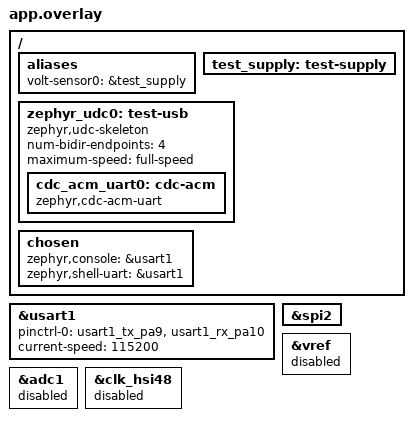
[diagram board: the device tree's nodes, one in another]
/* SPDX-License-Identifier: MIT */
#include "../../app/app.overlay"

/* Use the Zephyr USB stack and CDC ACM class with a software controller. */
/delete-node/ &zephyr_udc0;

/ {
	aliases {
		volt-sensor0 = &test_supply;
	};
	test_supply: test-supply {
	};
	zephyr_udc0: test-usb {
		compatible = "zephyr,udc-skeleton";
		num-bidir-endpoints = <4>;
		maximum-speed = "full-speed";
		cdc_acm_uart0: cdc-acm {
			compatible = "zephyr,cdc-acm-uart";
		};
	};
	chosen {
		zephyr,console = &usart1;
		zephyr,shell-uart = &usart1;
	};
};

&usart1 {
	pinctrl-0 = <&usart1_tx_pa9 &usart1_rx_pa10>;
	pinctrl-names = "default";
	current-speed = <115200>;
	status = "okay";
};

/* Exercise the pixel driver without the board's SPI DMA requests. */
&spi2 {
	/delete-property/ dmas;
	/delete-property/ dma-names;
};

&vref { status = "disabled"; };
&adc1 { status = "disabled"; };
&clk_hsi48 { status = "disabled"; };
